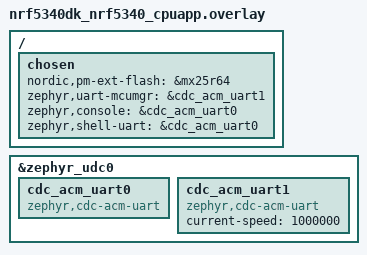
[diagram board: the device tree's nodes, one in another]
/ {
	chosen {
		nordic,pm-ext-flash = &mx25r64;
		zephyr,uart-mcumgr = &cdc_acm_uart1;
		zephyr,console = &cdc_acm_uart0;
		zephyr,shell-uart = &cdc_acm_uart0;
	};
};

&zephyr_udc0 {
	cdc_acm_uart0: cdc_acm_uart0 {
		compatible = "zephyr,cdc-acm-uart";
	};

	cdc_acm_uart1: cdc_acm_uart1 {
		current-speed=<1000000>;
		compatible = "zephyr,cdc-acm-uart";
	};

};
